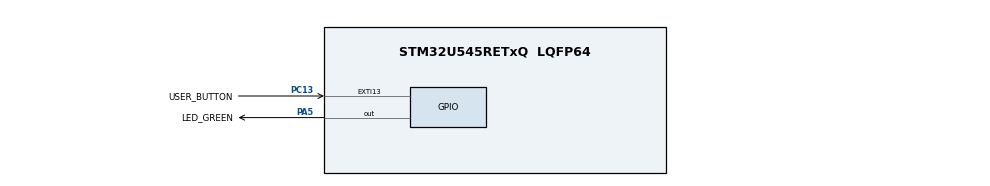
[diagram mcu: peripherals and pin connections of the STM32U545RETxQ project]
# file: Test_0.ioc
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CORTEX_M33_NS.userName=CORTEX_M33
Mcu.Family=STM32U5
Mcu.Name=STM32U545RETxQ
Mcu.Package=LQFP64
NVIC.PriorityGroup=NVIC_PRIORITYGROUP_4
PA5.GPIO_Label=LED_GREEN
PA5.GPIO_PuPd=GPIO_PULLUP
PA5.GPIO_Speed=GPIO_SPEED_FREQ_HIGH
PA5.Signal=GPIO_Output
PC13.GPIO_Label=USER_BUTTON
PC13.GPIO_ModeDefaultEXTI=GPIO_MODE_IT_FALLING
PC13.GPIO_PuPd=GPIO_PULLDOWN
PC13.Signal=GPXTI13
PWR.PowerMode=PWR_SMPS_SUPPLY
ProjectManager.HeapSize=0x200
ProjectManager.StackSize=0x400
ProjectManager.TargetToolchain=STM32CubeIDE
RCC.ADCFreq_Value=16000000
RCC.DACCLockSelectionVirtual=RCC_DAC1CLKSOURCE_LSI
RCC.DACCLockSelectionVirtualString=RCC_DAC1CLKSOURCE_LSI
RCC.EPOD_VALUE=4000000
RCC.HSE_VALUE=16000000
RCC.HSI48_VALUE=48000000
RCC.HSI_VALUE=16000000
RCC.LSE_VALUE=32768
RCC.LSIDIV_VALUE=32000
RCC.MSI_VALUE=4000000
RCC.USBFreq_Value=48000000
RCC.VCOOutputFreq_Value=516000000
VP_ICACHE_VS_ICACHE.Mode=DirectMappedCache
VP_LPBAMQUEUE_VS_QUEUE.Mode=QUEUEMODE
VP_LPBAM_VS_SIG1.Mode=SmartRun
VP_LPBAM_VS_SIG4.Mode=LPDMA1
VP_MEMORYMAP_VS_MEMORYMAP.Mode=CurAppReg
VP_NUCLEO-U545RE-Q_VS_BSP_COMMON.Mode=COMMON
VP_PWR_VS_LPOM.Mode=PowerOptimisation
VP_PWR_VS_SECSignals.Mode=Security/Privilege
board=NUCLEO-U545RE-Q

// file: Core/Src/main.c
/* USER CODE BEGIN Header */
/**
  ******************************************************************************
  * @file           : main.c
  * @brief          : Main program body
  ******************************************************************************
  * @attention
  *
  * Copyright (c) 2025 STMicroelectronics.
  * All rights reserved.
  *
  * This software is licensed under terms that can be found in the LICENSE file
  * in the root directory of this software component.
  * If no LICENSE file comes with this software, it is provided AS-IS.
  *
  ******************************************************************************
  */
/* USER CODE END Header */
#include "main.h"
#include "icache.h"
#include "gpio.h"

/* USER CODE BEGIN PV */
uint32_t blink_delays[]={5000,1000};
volatile uint8_t delay_index = 0;
uint32_t time_req;
uint32_t last_button_press_time=0;
/* USER CODE END PV */

void SystemClock_Config(void);
static void SystemPower_Config(void);
/* USER CODE BEGIN PFP */
void led_blink(uint32_t time_req);
void HAL_GPIO_EXTI_Callback(uint16_t GPIO_Pin);
/* USER CODE END PFP */

int main(void)
{

  /* MCU Configuration--------------------------------------------------------*/

  /* Reset of all peripherals, Initializes the Flash interface and the Systick. */
  HAL_Init();

  /* Configure the System Power */
  SystemPower_Config();

  /* Configure the system clock */
  SystemClock_Config();

  /* Initialize all configured peripherals */
  MX_GPIO_Init();
  MX_ICACHE_Init();

  /* Infinite loop */
  /* USER CODE BEGIN WHILE */
  while (1)
  {
	  led_blink(blink_delays[delay_index]);

    /* USER CODE END WHILE */

  }
}

void SystemClock_Config(void)
{
  RCC_OscInitTypeDef RCC_OscInitStruct = {0};
  RCC_ClkInitTypeDef RCC_ClkInitStruct = {0};

  /** Configure the main internal regulator output voltage
  */
  if (HAL_PWREx_ControlVoltageScaling(PWR_REGULATOR_VOLTAGE_SCALE4) != HAL_OK)
  {
    Error_Handler();
  }

  /** Initializes the CPU, AHB and APB buses clocks
  */
  RCC_OscInitStruct.OscillatorType = RCC_OSCILLATORTYPE_MSI;
  RCC_OscInitStruct.MSIState = RCC_MSI_ON;
  RCC_OscInitStruct.MSICalibrationValue = RCC_MSICALIBRATION_DEFAULT;
  RCC_OscInitStruct.MSIClockRange = RCC_MSIRANGE_4;
  RCC_OscInitStruct.PLL.PLLState = RCC_PLL_NONE;
  if (HAL_RCC_OscConfig(&RCC_OscInitStruct) != HAL_OK)
  {
    Error_Handler();
  }

  /** Initializes the CPU, AHB and APB buses clocks
  */
  RCC_ClkInitStruct.ClockType = RCC_CLOCKTYPE_HCLK|RCC_CLOCKTYPE_SYSCLK
                              |RCC_CLOCKTYPE_PCLK1|RCC_CLOCKTYPE_PCLK2
                              |RCC_CLOCKTYPE_PCLK3;
  RCC_ClkInitStruct.SYSCLKSource = RCC_SYSCLKSOURCE_MSI;
  RCC_ClkInitStruct.AHBCLKDivider = RCC_SYSCLK_DIV1;
  RCC_ClkInitStruct.APB1CLKDivider = RCC_HCLK_DIV1;
  RCC_ClkInitStruct.APB2CLKDivider = RCC_HCLK_DIV1;
  RCC_ClkInitStruct.APB3CLKDivider = RCC_HCLK_DIV1;

  if (HAL_RCC_ClockConfig(&RCC_ClkInitStruct, FLASH_LATENCY_0) != HAL_OK)
  {
    Error_Handler();
  }
}

/**
  * @brief Power Configuration
  * @retval None
  */
static void SystemPower_Config(void)
{

  /*
   * Switch to SMPS regulator instead of LDO
   */
  if (HAL_PWREx_ConfigSupply(PWR_SMPS_SUPPLY) != HAL_OK)
  {
    Error_Handler();
  }
}

/* USER CODE BEGIN 4 */

void led_blink(uint32_t time_req)
{
	HAL_Delay(time_req);
	HAL_GPIO_TogglePin(LED_GREEN_GPIO_Port,LED_GREEN_Pin);
}

void HAL_GPIO_EXTI_Falling_Callback(uint16_t GPIO_Pin)
{
	if(GPIO_Pin == GPIO_PIN_13)
	{
		if(HAL_GetTick()-last_button_press_time>200)
		{
			delay_index++;
			if (delay_index >= (sizeof(blink_delays))/(sizeof(uint32_t)))
			{
				delay_index = 0;
			}

			last_button_press_time = HAL_GetTick();
		}
	}
}

/* USER CODE END 4 */

void Error_Handler(void)
{
  __disable_irq();
  while (1)
  {
  }
}
